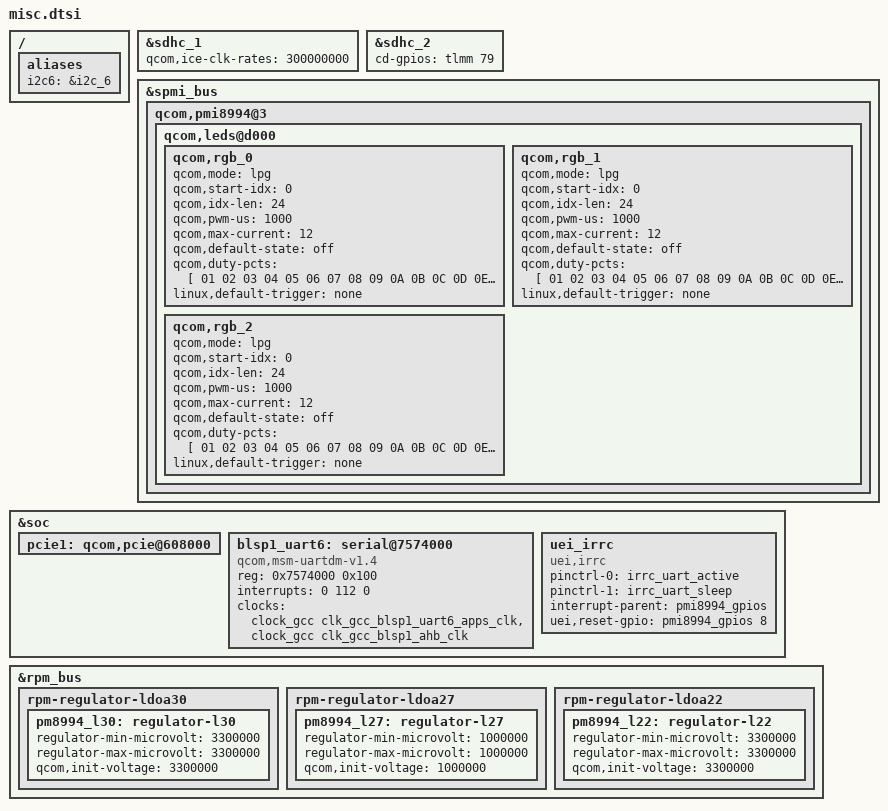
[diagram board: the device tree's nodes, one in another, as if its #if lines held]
/* Copyright (c) 2015, The Linux Foundation. All rights reserved.
 *
 * This program is free software; you can redistribute it and/or modify
 * it under the terms of the GNU General Public License version 2 and
 * only version 2 as published by the Free Software Foundation.
 *
 * This program is distributed in the hope that it will be useful,
 * but WITHOUT ANY WARRANTY; without even the implied warranty of
 * MERCHANTABILITY or FITNESS FOR A PARTICULAR PURPOSE.  See the
 * GNU General Public License for more details.
 */

/ {
	aliases {
		i2c6 = &i2c_6;
	};
};

&sdhc_1 {
	/* LG seemingly doesn't want the lower clock option */
	qcom,ice-clk-rates = <300000000>;
};

&sdhc_2 {
	/* Though Active-Low-H/W-logic is actually adopted in circuit-diagram,
	Logic-value is reversed in 3in2-socket not in 2in1-socket.
	1: Active-Low, 0: Active-High
	*/
#if defined(CONFIG_MACH_MSM8996_ELSA_DCM_JP) || defined(CONFIG_MACH_MSM8996_ELSA_KDDI_JP)
	cd-gpios = <&tlmm 79 0x0>;
#else
	cd-gpios = <&tlmm 95 0x1>; /* same as msm8996-mtp.dtsi */
#endif
};

/* LED setting */
&spmi_bus {
	qcom,pmi8994@3 {
		qcom,leds@d000 {
			status = "okay";
			qcom,rgb_0 {
				qcom,mode = "lpg";
				qcom,start-idx = <0>;
				qcom,idx-len = <24>;
				qcom,pwm-us = <1000>;
				qcom,max-current = <12>;
				qcom,default-state = "off";
				qcom,duty-pcts = [
					 01 02 03 04 05 06 07 08
					 09 0A 0B 0C 0D 0E 0F 10
					 11 12 13 14 15 16 17 18
					 ];
				linux,default-trigger = "none";
			};

			qcom,rgb_1 {
				qcom,mode = "lpg";
				qcom,start-idx = <0>;
				qcom,idx-len = <24>;
				qcom,pwm-us = <1000>;
				qcom,max-current = <12>;
				qcom,default-state = "off";
				qcom,duty-pcts = [
					 01 02 03 04 05 06 07 08
					 09 0A 0B 0C 0D 0E 0F 10
					 11 12 13 14 15 16 17 18
					 ];
				linux,default-trigger = "none";
			};

			qcom,rgb_2 {
				qcom,mode = "lpg";
				qcom,start-idx = <0>;
				qcom,idx-len = <24>;
				qcom,pwm-us = <1000>;
				qcom,max-current = <12>;
				qcom,default-state = "off";
				qcom,duty-pcts = [
					 01 02 03 04 05 06 07 08
					 09 0A 0B 0C 0D 0E 0F 10
					 11 12 13 14 15 16 17 18
					 ];
				linux,default-trigger = "none";
			};
		};
	};
};

&soc {
	pcie1: qcom,pcie@608000 {
		/delete-property/ perst-gpio;
		/delete-property/ wake-gpio;
	};

	blsp1_uart6: serial@7574000 {
		compatible = "qcom,msm-uartdm-v1.4", "qcom,msm-uartdm";
		reg = <0x7574000 0x100>;
		interrupts = <0 112 0>;
		status = "ok";
		clocks = <&clock_gcc clk_gcc_blsp1_uart6_apps_clk>,
				<&clock_gcc clk_gcc_blsp1_ahb_clk>;
		clock-names = "core", "iface";
	};

	uei_irrc {
		compatible = "uei,irrc";
		status = "ok";
		pinctrl-names = "ir_active", "ir_sleep";
		pinctrl-0 = <&irrc_uart_active>;
		pinctrl-1 = <&irrc_uart_sleep>;
		interrupt-parent = <&pmi8994_gpios>;
		uei,reset-gpio = <&pmi8994_gpios 8 0>;
	};
};

&rpm_bus {
	rpm-regulator-ldoa30 {
		status = "okay";
		pm8994_l30: regulator-l30 {
			regulator-min-microvolt = <3300000>;
			regulator-max-microvolt = <3300000>;
			qcom,init-voltage = <3300000>;
			status = "okay";
		};
	};

	rpm-regulator-ldoa27 {
		status = "okay";
		pm8994_l27: regulator-l27 {
			regulator-min-microvolt = <1000000>;
			regulator-max-microvolt = <1000000>;
			qcom,init-voltage = <1000000>;
			status = "okay";
		};
	};

	rpm-regulator-ldoa22 {
		status = "okay";
		pm8994_l22: regulator-l22 {
			regulator-min-microvolt = <3300000>;
			regulator-max-microvolt = <3300000>;
			qcom,init-voltage = <3300000>;
			status = "okay";
		};
	};
};
